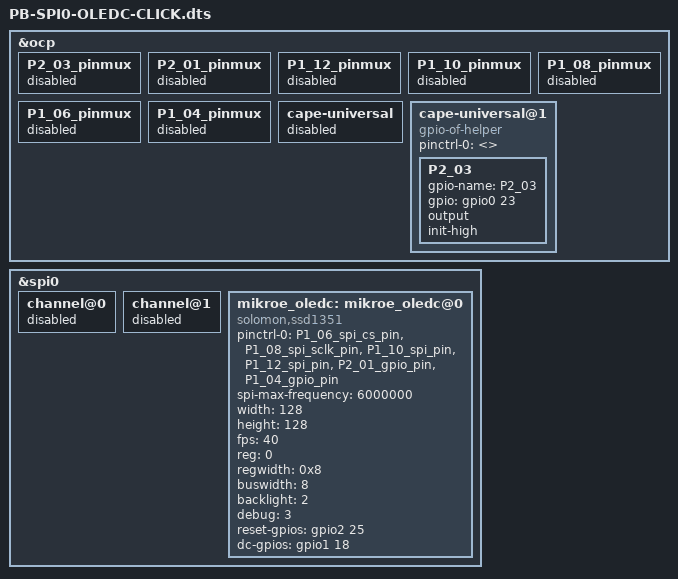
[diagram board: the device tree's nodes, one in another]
/*
 * Copyright (C) 2018 Texas Instruments, Jason Kridner <jdk@ti.com>
 * Copyright (C) 2018 Octavo Systems, Neeraj Dantu <neeraj.dantu@octavosystems.com>
 *
 * This program is free software; you can redistribute it and/or modify
 * it under the terms of the GNU General Public License version 2 as
 * published by the Free Software Foundation.
 *
 * https://www.mikroe.com/oled-c-click
 * https://download.mikroe.com/documents/add-on-boards/click/oled-c/oled-c-click-schematic-v101.pdf
 */

/dts-v1/;
/plugin/;

#include <dt-bindings/gpio/gpio.h>
#include <dt-bindings/pinctrl/am33xx.h>
#include <dt-bindings/interrupt-controller/irq.h>

/ {
	/*
	 * Free up the pins used by the cape from the pinmux helpers.
	 */
	fragment@0 {
		target = <&ocp>;
		__overlay__ {
			P2_03_pinmux { status = "disabled"; };  /* EN - gpio0_23*/
			P2_01_pinmux { status = "disabled"; };	/* D/C - gpio1_18 */
			P1_12_pinmux { status = "disabled"; };	/* MOSI - gpio0_4 */
			P1_10_pinmux { status = "disabled"; };	/* MISO - gpio0_3 */
			P1_08_pinmux { status = "disabled"; };	/* CLK - gpio0_2 */
			P1_06_pinmux { status = "disabled"; };	/* CS - gpio0_5 */
			P1_04_pinmux { status = "disabled"; };	/* RST - gpio2_25 */
			cape-universal { status = "disabled"; };
			cape-universal@1 { status = "disabled"; };
		};
	};

	fragment@1 {
		target = <&spi0>;
		__overlay__ {
			#address-cells = <1>;
			#size-cells = <0>;
			status = "okay";

			channel@0 {
				status = "disabled";
			};
			channel@1 {
				status = "disabled";
			};

			mikroe_oledc: mikroe_oledc@0{
				compatible = "solomon,ssd1351";
				pinctrl-names = "default";
				pinctrl-0 = <
					&P1_06_spi_cs_pin
					&P1_08_spi_sclk_pin
					&P1_10_spi_pin
					&P1_12_spi_pin
					&P2_01_gpio_pin
					&P1_04_gpio_pin
				>;
				spi-max-frequency = <6000000>;
				width = <128>;
				height = <128>;
				fps = <40>;
				reg = <0>;
				regwidth = <0x8>;
				buswidth = <8>;
				backlight = <2>;
				debug = <3>;
				reset-gpios = <&gpio2 25 0>;
				dc-gpios = <&gpio1 18 0>;
			};
		};
		
	};
	
	fragment@2 {
		target = <&ocp>;
		__overlay__ {
			cape-universal@1 {
				compatible = "gpio-of-helper";
				status = "okay";
				pinctrl-names = "default";
				pinctrl-0 = <>;

				P2_03 {
					gpio-name = "P2_03";
					gpio = <&gpio0 23 0>;
					output;
					init-high;
				};
			};
		};
	};
};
